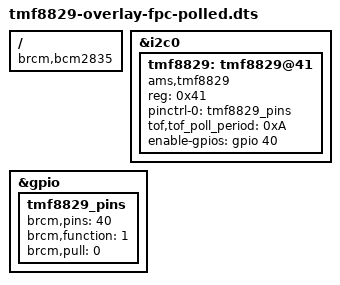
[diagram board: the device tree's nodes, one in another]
/*
 ************************************************************************************
 * Copyright (c) [2025] ams-OSRAM AG                                                *
 *                                                                                  *
 * SPDX-License-Identifier: GPL-2.0 OR MIT                                          *
 *                                                                                  *
 * For the full license texts, see LICENSES-GPL-2.0.txt or LICENSES-MIT.TXT.        *
 ************************************************************************************
*/

/* Definitions for tmf8829 time-of-flight sensor from ams AG
 *
 * Compile:
 * dtc -@ -I dts -O dtb -o tmf8829-overlay-fpc_polled.dtbo tmf8829-overlay-fpc_polled.dts
 */

/dts-v1/;
/plugin/;

/ {
  compatible = "brcm,bcm2835","brcm,bcm2708","brcm,bcm2709";

  fragment@0 {
    target = <&i2c0>;
    __overlay__ {
      status = "okay";
    };
  };

  fragment@1 {
    target = <&gpio>;
    __overlay__ {
      tmf8829_pins: tmf8829_pins {
        brcm,pins = <40>; /*enable (CAM_IO1->GPIO40)*/
        brcm,function = <1>; /*enable output*/
        brcm,pull = <0>; /*enable pull-down on CE*/
      };
    };
  };

  fragment@2 {
    target = <&i2c0>;
    __overlay__ {
      #address-cells = <1>;
      #size-cells = <0>;
      status = "okay";

      tmf8829: tmf8829@41 {
        compatible = "ams,tmf8829";
        reg = <0x41>; /* x41 for HW */
        pinctrl-names = "default";
        pinctrl-0 = <&tmf8829_pins>;
        tof,tof_poll_period = <0xA>; /*poll period (100 usec)*/
        enable-gpios = <&gpio 40 0>; /* CAM_GPIO1 on header*/
      };
    };
  };

  __overrides__ {
    tof_poll_period = <&tmf8829>,"tof,tof_poll_period:0";
    tof_enable = <&tmf8829_pins>,"brcm,pins:0",
        <&tmf8829>,"enable-gpios:4";
    tof_i2c_addr = <&tmf8829>,"reg:0";
  };
};

